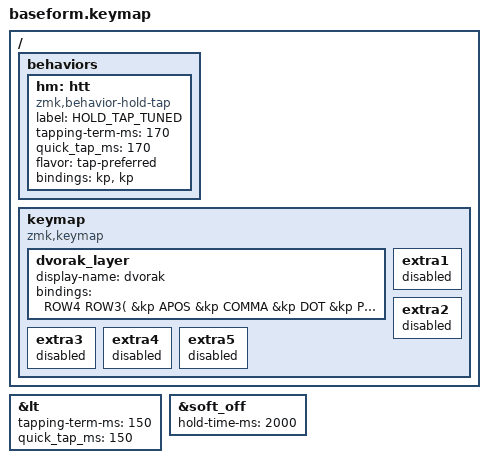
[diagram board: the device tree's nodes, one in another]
#include <behaviors.dtsi>
#include <dt-bindings/zmk/keys.h>
#include <dt-bindings/zmk/bt.h>
#include <dt-bindings/zmk/ext_power.h>
#include <dt-bindings/zmk/outputs.h>
#include "../layer_defs.dtsi"
#include "../keymap_edges.dtsi"

#define DVO 0

&lt {
  tapping-term-ms = <150>;
  quick_tap_ms = <150>;
};

&soft_off {
    hold-time-ms = <2000>; 
};

/ {

  behaviors {
    hm: htt {
      compatible = "zmk,behavior-hold-tap";
      label = "HOLD_TAP_TUNED";
      #binding-cells = <2>;
      tapping-term-ms = <170>;
      quick_tap_ms = <170>;
      flavor = "tap-preferred";
      bindings = <&kp>, <&kp>;
    };
  };

  keymap {
    compatible = "zmk,keymap";

    dvorak_layer {
      display-name = "dvorak";
      bindings = <
        ROW4
        ROW3( &kp APOS        &kp COMMA   &kp DOT  &kp P  &kp Y    &kp F  &kp G  &kp C  &kp R       &kp L       )
        ROW2( &kp A           &kp O       &kp E    &kp U  &kp I    &kp D  &kp H  &kp T  &kp N       &kp S       )
        ROW1( &hm LCTRL COLN  &hm LALT Q  &kp J    &kp K  &kp X    &kp B  &kp M  &kp W  &hm RALT V  &hm RCTRL Z )
        THUMB_ROW
      >;
    };
 
#include "../shared_layers.dtsi"

    extra1 {
        status = "reserved";
    };

    extra2 {
        status = "reserved";
    };

    extra3 {
        status = "reserved";
    };

    extra4 {
        status = "reserved";
    };

    extra5 {
        status = "reserved";
    };


  };
};
